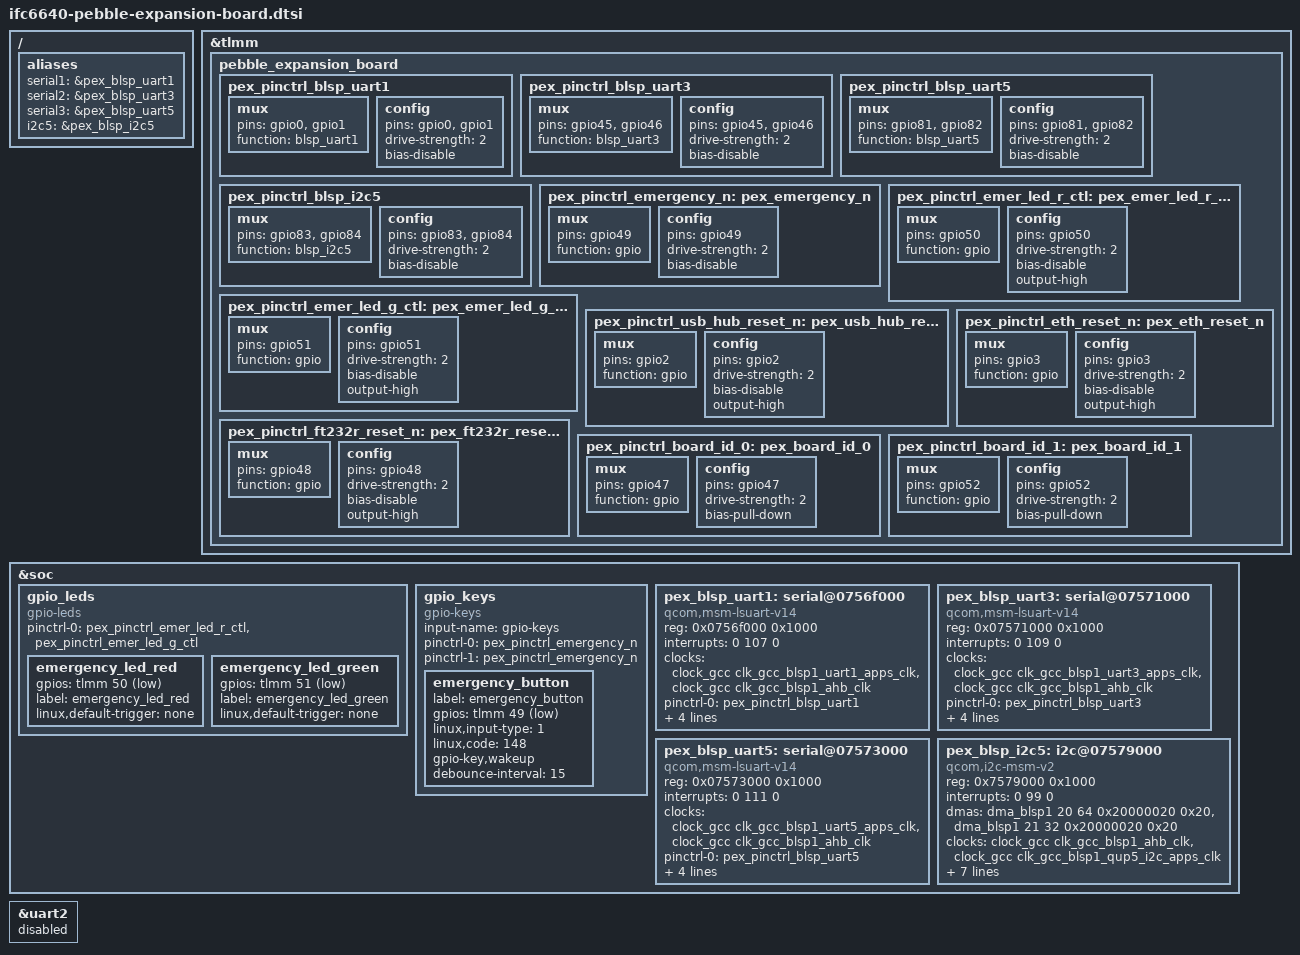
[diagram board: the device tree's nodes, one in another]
/*
    Sensity Pebble Expansion Board v1 for IFC6640 boards

    Reference:
    https://lqdwifi.atlassian.net/wiki/spaces/BBV5/pages/3253792/Design+information
*/

/*
    GPIO   | DT function     | PEB Rev C            | PEB Rev B            | PEB Rev A (not supported)
    -------|-----------------|----------------------|----------------------|--------------------------
    GPIO0  | BLSP1_UART_TX   | out DISPLAY_UART_TXD | out TICKER_1_TXD     | out TICKER_1_TXD     |
    GPIO1  | BLSP1_UART_RX   | in  DISPLAY_UART_RXD | in  TICKER_1_RXD     | in  TICKER_1_RXD     |
    GPIO2  | GPIO OUT        | out USB_HUB_RESET_N  | out USB_HUB_RESET_N  | out USB_HUB_RESET_N  |
    GPIO3  | GPIO OUT        | out ETH_RESET_N      | out ETH_RESET_N      | out ETH_RESET_N      |
    GPIO25 |                 |                      |                      | out EC25_WAKEUP_IN   |
    GPIO26 |                 | out USB2_PRT_CTL     |                      | out EC25_DISABLE_N   |
    GPIO27 |                 | in  USB2_PRT_FLT_N   |                      | out EC25_RESET       |
    GPIO28 |                 |                      |                      | out EC25_PWRKEY      |
    GPIO45 | BLSP3_UART_TX   | out SPARE_UART_TXD   | out TICKER_2_TXD     | out TICKER_2_TXD     |
    GPIO46 | BLSP3_UART_RX   | in  SPARE_UART2_RXD  | in  TICKER_2_RXD     | in  TICKER_2_RXD     |
    GPIO47 | GPIO IN         | in  BOARD_ID_0       | in  BOARD_ID_0       | in  BOARD_ID_0       |
    GPIO48 | GPIO OUT        |                      | out FT232R_RESET_N   | out FT232R_RESET_N   |
    GPIO49 | GPIO_KEYS       | in  EMERGENCY_N      | in  EMERGENCY_N      | in  EMERGENCY_N      |
    GPIO50 | GPIO_LEDS RED   | out EMER_LED_R_CTL   | out EMER_LED_R_CTL   | out EMER_LED_R_CTL   |
    GPIO51 | GPIO_LEDS GREEN | out EMER_LED_G_CTL   | out EMER_LED_G_CTL   | out EMER_LED_G_CTL   |
    GPIO52 | GPIO IN         | in  BOARD_ID_1       | in  BOARD_ID_1       | in  EC25_AP_READY    |
    GPIO81 | BLSP5_UART_TX   | out BATTERY_TXD      | out BATTERY_TXD      | out BATTERY_TXD      |
    GPIO82 | BLSP5_UART_RX   | in  BATTERY_RXD      | in  BATTERY_RXD      | in  BATTERY_RXD      |
    GPIO83 |                 | io  TEMP_I2C_SDA     | io  TEMP_I2C_SDA     |                      |
    GPIO84 |                 | out TEMP_I2C_SCL     | out TEMP_I2C_SCL     |                      |


    Board | ID[1:0]
    ------|--------
    Rev B | 10
    Rev C | 01
*/

/*
    Append Pebble Expansion Board GPIO setup to the "Top Level Mode Multiplexer" node from msm8996-pinctrl.dtsi

    These don't actually do anything unless they're activated from something else

    Reference documentation: Documentation/devicetree/bindings/pinctrl/qcom,msm8996-pinctrl.txt
    "pins"
        A list of pins that can be set to the same function

    "function"
        This is the alternative function of the pin.
        These are listed in the array msm8996_groups from drivers/pinctrl/qcom/pinctrl-msm8996.c
        Each line contains the pin number, and then the alternative functions available for that pin

    "drive-strength"
        Drive strength for the pin, in milliamps.

    "bias-disable", "bias-pull-down", "bias-pull-up"
        Should pin have a pull-up resistor or pull-down resistor?

    "output-high", "output-low"
        Default output state of pin
*/
&tlmm {
    pebble_expansion_board: pebble_expansion_board {
        /* UARTs */
        pex_pinctrl_blsp_uart1: pex_pinctrl_blsp_uart1 {
            mux    { pins = "gpio0", "gpio1"; function = "blsp_uart1"; };
            config { pins = "gpio0", "gpio1"; drive-strength = <2>; bias-disable; };
        };
        pex_pinctrl_blsp_uart3: pex_pinctrl_blsp_uart3 {
            mux    { pins = "gpio45", "gpio46"; function = "blsp_uart3"; };
            config { pins = "gpio45", "gpio46"; drive-strength = <2>; bias-disable; };
        };
        pex_pinctrl_blsp_uart5: pex_pinctrl_blsp_uart5 {
            mux    { pins = "gpio81", "gpio82"; function = "blsp_uart5"; };
            config { pins = "gpio81", "gpio82"; drive-strength = <2>; bias-disable; };
        };

        /* I2C busses */
        pex_pinctrl_blsp_i2c5: pex_pinctrl_blsp_i2c5 {
            mux    { pins = "gpio83", "gpio84"; function = "blsp_i2c5"; };
            config { pins = "gpio83", "gpio84"; drive-strength = <2>; bias-disable; };
        };

        /* GPIO emergency button + emergency LEDs */
        pex_pinctrl_emergency_n: pex_emergency_n {
            mux    { pins = "gpio49"; function = "gpio"; };
            config { pins = "gpio49"; drive-strength = <2>; bias-disable; };
        };
        pex_pinctrl_emer_led_r_ctl: pex_emer_led_r_ctl {
            mux    { pins = "gpio50"; function = "gpio"; };
            config { pins = "gpio50"; drive-strength = <2>; bias-disable; output-high; };
        };
        pex_pinctrl_emer_led_g_ctl: pex_emer_led_g_ctl {
            mux    { pins = "gpio51"; function = "gpio"; };
            config { pins = "gpio51"; drive-strength = <2>; bias-disable; output-high; };
        };

        /* Chip reset lines */
        pex_pinctrl_usb_hub_reset_n: pex_usb_hub_reset_n {
            mux    { pins = "gpio2"; function = "gpio"; };
            config { pins = "gpio2"; drive-strength = <2>; bias-disable; output-high; };
        };
        pex_pinctrl_eth_reset_n: pex_eth_reset_n {
            mux    { pins = "gpio3"; function = "gpio"; };
            config { pins = "gpio3"; drive-strength = <2>; bias-disable; output-high; };
        };
        pex_pinctrl_ft232r_reset_n: pex_ft232r_reset_n {
            mux    { pins = "gpio48"; function = "gpio"; };
            config { pins = "gpio48"; drive-strength = <2>; bias-disable; output-high; };
        };

        /* Board ID inputs */
        pex_pinctrl_board_id_0: pex_board_id_0 {
            mux    { pins = "gpio47"; function = "gpio"; };
            config { pins = "gpio47"; drive-strength = <2>; bias-pull-down; };
        };
        pex_pinctrl_board_id_1: pex_board_id_1 {
            mux    { pins = "gpio52"; function = "gpio"; };
            config { pins = "gpio52"; drive-strength = <2>; bias-pull-down; };
        };
    };
};

&soc {
    /*
        Documentation/devicetree/bindings/leds/leds-gpio.txt
    */
    gpio_leds {
        compatible = "gpio-leds";
        pinctrl-names = "default";
        pinctrl-0 = <&pex_pinctrl_emer_led_r_ctl &pex_pinctrl_emer_led_g_ctl>;

        /*
            /sys/devices/soc/soc:gpio_leds/leds/emergency_led_red/brightness
        */
        emergency_led_red {
            gpios = <&tlmm 50 1>;
            label = "emergency_led_red";
            linux,default-trigger = "none";
        };

        /*
            /sys/devices/soc/soc:gpio_leds/leds/emergency_led_green/brightness
        */
        emergency_led_green {
            gpios = <&tlmm 51 1>;
            label = "emergency_led_green";
            linux,default-trigger = "none";
        };
    };

    /*
        Documentation/devicetree/bindings/gpio/gpio_keys.txt
        This extends the node from apq8096-sbc.dtsi
        (There can only be one instance of the gpio-keys node!)
    */
    gpio_keys {
        compatible = "gpio-keys";
        input-name = "gpio-keys";
        pinctrl-names = "tlmm_gpio_key_active", "tlmm_gpio_key_suspend";
        pinctrl-0 = <&pex_pinctrl_emergency_n>;
        pinctrl-1 = <&pex_pinctrl_emergency_n>;

        /*
            Generate a "PROG1" key event on the "gpio-keys" input device
        */
        emergency_button {
            label = "emergency_button";
            gpios = <&tlmm 49 1>;
            linux,input-type = <1>; // EV_KEY
            linux,code = <148>; // KEY_PROG1
            gpio-key,wakeup; // Wakeup the device if it's sleeping
            debounce-interval = <15>;
        };
    };

    /*
    UART hardware table
    -------------------

    Hardware | Clock domain | IRQ | Address    (Size)   | Comment
    ---------|--------------|-----|---------------------|------------
    BLSP1    | blsp1_uart1  | 107 | 0x0756F000 (0x1000) | pex_blsp_uart1
    BLSP2    | blsp1_uart2  | 108 | 0x07570000 (0x1000) | uartblsp1dm1 (msm8996.dtsi)
    BLSP3    | blsp1_uart3  | 109 | 0x07571000 (0x1000) | pex_blsp_uart3
    BLSP4    | blsp1_uart4  | 110 | 0x07572000 (0x1000) |
    BLSP5    | blsp1_uart5  | 111 | 0x07573000 (0x1000) | pex_blsp_uart5
    BLSP6    | blsp1_uart6  | 112 | 0x07574000 (0x1000) |
    ---------|--------------|-----|---------------------|
    BLSP7    | blsp2_uart1  | 113 | 0x075AF000 (0x1000) |
    BLSP8    | blsp2_uart2  | 114 | 0x075B0000 (0x1000) | uartblsp2dm1 (msm8996.dtsi) - Debug Console
    BLSP9    | blsp2_uart3  | 115 | 0x075B1000 (0x1000) |
    BLSP10   | blsp2_uart4  | 116 | 0x075B2000 (0x1000) |
    BLSP11   | blsp2_uart5  | 117 | 0x075B3000 (0x1000) |
    BLSP12   | blsp2_uart6  | 118 | 0x075B4000 (0x1000) | uart2 (msm8996.dtsi) - Bluetooth?
    */

    // "BLSP1"
    pex_blsp_uart1: serial@0756f000 {
        // Use the drivers/tty/serial/msm_serial_hs_lite.c driver
        compatible = "qcom,msm-lsuart-v14";

        // IO space for UART (see above table)
        reg = <0x0756f000 0x1000>;

        // Interrupt number for UART (see above table)
        interrupts = <0 107 0>;

        // Clock domains for UART (see above table)
        clock-names = "core_clk", "iface_clk";
        clocks = <&clock_gcc clk_gcc_blsp1_uart1_apps_clk>, <&clock_gcc clk_gcc_blsp1_ahb_clk>;

        // Pin control setup
        pinctrl-names = "default";
        pinctrl-0 = <&pex_pinctrl_blsp_uart1>;

        // GPIO setup only TXD and RXD (no RTS/CTS/etc)
        qcom,config-gpio = <2>;
        qcom,tx-gpio = <&tlmm 0 0>;
        qcom,rx-gpio = <&tlmm 1 0>;
        qcom,use-pm;

        // Engage!
        status = "ok";
    };

    // "BLSP3"
    pex_blsp_uart3: serial@07571000 {
        // Use the drivers/tty/serial/msm_serial_hs_lite.c driver
        compatible = "qcom,msm-lsuart-v14";

        // IO space for UART (see above table)
        reg = <0x07571000 0x1000>;

        // Interrupt number for UART (see above table)
        interrupts = <0 109 0>;

        // Clock domains for UART (see above table)
        clock-names = "core_clk", "iface_clk";
        clocks = <&clock_gcc clk_gcc_blsp1_uart3_apps_clk>, <&clock_gcc clk_gcc_blsp1_ahb_clk>;

        // Pin control setup
        pinctrl-names = "default";
        pinctrl-0 = <&pex_pinctrl_blsp_uart3>;

        // GPIO setup only TXD and RXD (no RTS/CTS/etc)
        qcom,config-gpio = <2>;
        qcom,tx-gpio = <&tlmm 45 0>;
        qcom,rx-gpio = <&tlmm 46 0>;
        qcom,use-pm;

        // Engage!
        status = "ok";
    };

    // BLSP5
    pex_blsp_uart5: serial@07573000 {
        // Use the drivers/tty/serial/msm_serial_hs_lite.c driver
        compatible = "qcom,msm-lsuart-v14";

        // IO space for UART (see above table)
        reg = <0x07573000 0x1000>;

        // Interrupt number for UART (see above table)
        interrupts = <0 111 0>;

        // Clock domains for UART (see above table)
        clock-names = "core_clk", "iface_clk";
        clocks = <&clock_gcc clk_gcc_blsp1_uart5_apps_clk>, <&clock_gcc clk_gcc_blsp1_ahb_clk>;

        // Pin control setup
        pinctrl-names = "default";
        pinctrl-0 = <&pex_pinctrl_blsp_uart5>;

        // GPIO setup only TXD and RXD (no RTS/CTS/etc)
        qcom,config-gpio = <2>;
        qcom,tx-gpio = <&tlmm 81 0>;
        qcom,rx-gpio = <&tlmm 82 0>;
        qcom,use-pm;

        // Engage!
        status = "ok";
    };


    /*
    QUP hardware table
    -------------------
                                                        | BAM Pipe  |
    Hardware | Clock domain | IRQ | Address    (Size)   | TX  | RX  | Comment
    ---------|--------------|-----|---------------------|-----|-----|
    BLSP1    | blsp1_qup1   | 95  | 0x7575000 (0x1000)  | 12  | 13  |
    BLSP2    | blsp1_qup2   | 96  | 0x7576000 (0x1000)  | 14  | 15  |
    BLSP3    | blsp1_qup3   | 97  | 0x7577000 (0x1000)  | 16  | 17  |
    BLSP4    | blsp1_qup4   | 98  | 0x7578000 (0x1000)  | 18  | 19  |
    BLSP5    | blsp1_qup5   | 99  | 0x7579000 (0x1000)  | 20  | 21  | pex_blsp_i2c_5 (temperature sensor)
    BLSP6    | blsp1_qup6   | 100 | 0x757A000 (0x1000)  | 22  | 23  |
    ---------|--------------|-----|---------------------|-----|-----|
    BLSP7    | blsp2_qup1   | 101 | 0x75B5000 (0x1000)  | 12  | 13  |
    BLSP8    | blsp2_qup2   | 102 | 0x75B6000 (0x1000)  | 14  | 15  |
    BLSP9    | blsp2_qup3   | 103 | 0x75B7000 (0x1000)  | 16  | 17  |
    BLSP10   | blsp2_qup4   | 104 | 0x75B8000 (0x1000)  | 18  | 19  |
    BLSP11   | blsp2_qup5   | 105 | 0x75B9000 (0x1000)  | 20  | 21  |
    BLSP12   | blsp2_qup6   | 106 | 0x75BA000 (0x1000)  | 22  | 23  |

    See: Documentation//devicetree/bindings/i2c/i2c-msm-v2.txt
    */
    pex_blsp_i2c5: i2c@07579000 {
        #address-cells = <1>;
        #size-cells = <0>;

        // Use the drivers/i2c/busses/i2c-msm-v2.c driver
        compatible = "qcom,i2c-msm-v2";

        // IO space for QUP controller (see above table)
        reg-names = "qup_phys_addr";
        reg = <0x7579000 0x1000>;

        // Interrupt number for QUP controller (see above table)
        interrupt-names = "qup_irq";
        interrupts = <0 99 0>;

        // BAM DMA Pipes for QUP controller (see above table)
        dma-names = "tx", "rx";
        dmas = <&dma_blsp1 20 64 0x20000020 0x20>, <&dma_blsp1 21 32 0x20000020 0x20>;

        // Clock domains for bus (see above table)
        clock-names = "iface_clk", "core_clk";
        clocks = <&clock_gcc clk_gcc_blsp1_ahb_clk>, <&clock_gcc clk_gcc_blsp1_qup5_i2c_apps_clk>;

        // Pin control setup
        pinctrl-names = "i2c_active", "i2c_sleep";
        pinctrl-0 = <&pex_pinctrl_blsp_i2c5>;
        pinctrl-1 = <&pex_pinctrl_blsp_i2c5>;

        // Setup bus master to BLSP1 complex
        qcom,master-id = <MSM_BUS_MASTER_BLSP_1>;

        // Input clock (fixed at 19.2MHz)
        qcom,clk-freq-in  = <19200000>;

        // I2C clock, 100KHz standard speed mode (can also be 400KHz for full speed mode)
        qcom,clk-freq-out = <100000>;

        // Noise rejection levels can be between 0 and 3
        qcom,noise-rjct-scl = <0>;
        qcom,noise-rjct-sda = <0>;

        // Engage!
        status = "ok";
    };
};

// Disable ttyHSL2
&uart2 {
    status = "disabled";
};

/ {
    aliases {
        // Ensure device node numbering is consistent
        serial1 = &pex_blsp_uart1;
        serial2 = &pex_blsp_uart3;
        serial3 = &pex_blsp_uart5;
        i2c5 = &pex_blsp_i2c5;
    };
};
